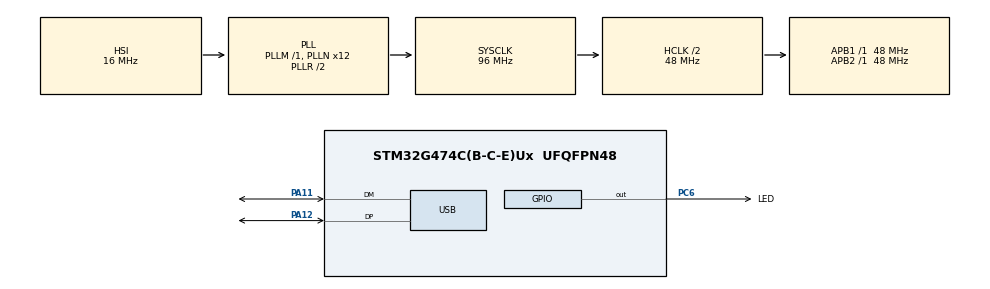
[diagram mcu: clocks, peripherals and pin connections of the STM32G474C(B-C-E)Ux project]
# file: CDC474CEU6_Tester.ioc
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Mcu.Family=STM32G4
Mcu.Name=STM32G474C(B-C-E)Ux
Mcu.Package=UFQFPN48
NVIC.PriorityGroup=NVIC_PRIORITYGROUP_4
NVIC.USB_LP_IRQn=true\:0\:0\:false\:false\:true\:false\:true\:true
PA11.Mode=Device
PA11.Signal=USB_DM
PA12.Mode=Device
PA12.Signal=USB_DP
PA13.Mode=Serial_Wire
PA13.Signal=SYS_JTMS-SWDIO
PA14.Mode=Serial_Wire
PA14.Signal=SYS_JTCK-SWCLK
PC6.GPIO_Label=LED
PC6.Signal=GPIO_Output
ProjectManager.HeapSize=0x200
ProjectManager.StackSize=0x400
ProjectManager.TargetToolchain=EWARM V8.50
RCC.ADC12Freq_Value=96000000
RCC.ADC345Freq_Value=96000000
RCC.AHBCLKDivider=RCC_SYSCLK_DIV2
RCC.AHBFreq_Value=48000000
RCC.APB1Freq_Value=48000000
RCC.APB1TimFreq_Value=48000000
RCC.APB2Freq_Value=48000000
RCC.APB2TimFreq_Value=48000000
RCC.CortexFreq_Value=48000000
RCC.EXTERNAL_CLOCK_VALUE=12288000
RCC.HCLKFreq_Value=48000000
RCC.HSE_VALUE=8000000
RCC.HSI48_VALUE=48000000
RCC.HSI_VALUE=16000000
RCC.LSE_VALUE=32768
RCC.PLLN=12
RCC.PLLQ=RCC_PLLQ_DIV4
RCC.SYSCLKFreq_VALUE=96000000
RCC.SYSCLKSource=RCC_SYSCLKSOURCE_PLLCLK
RCC.USBFreq_Value=48000000
RCC.VCOOutputFreq_Value=192000000
USB_DEVICE.CLASS_NAME_FS=CDC
USB_DEVICE.USBD_SELF_POWERED=0
USB_DEVICE.VirtualMode=Cdc
USB_DEVICE.VirtualModeFS=Cdc_FS
VP_SYS_VS_DBSignals.Mode=DisableDeadBatterySignals
VP_USB_DEVICE_VS_USB_DEVICE_CDC_FS.Mode=CDC_FS
board=custom

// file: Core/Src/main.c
/* USER CODE BEGIN Header */
/**
  ******************************************************************************
  * @file           : main.c
  * @brief          : Main program body
  ******************************************************************************
  * @attention
  *
  * Copyright (c) 2025 STMicroelectronics.
  * All rights reserved.
  *
  * This software is licensed under terms that can be found in the LICENSE file
  * in the root directory of this software component.
  * If no LICENSE file comes with this software, it is provided AS-IS.
  *
  ******************************************************************************
  */
/* USER CODE END Header */
#include "main.h"
#include "usb_device.h"

/* USER CODE BEGIN Includes */
#include "string.h"
#include "usbd_cdc_if.h"
/* USER CODE END Includes */

/* USER CODE BEGIN PV */
char * message = "Hello world!\n";
char buffer[256] = {0};
char ipbuff[256] = {0};
uint16_t msg_size = 0;
uint32_t counter = 0;
uint32_t ticks = 0;

extern USBD_HandleTypeDef hUsbDeviceFS;

/* USER CODE END PV */

void SystemClock_Config(void);
static void MX_GPIO_Init(void);

int main(void)
{

  /* MCU Configuration--------------------------------------------------------*/

  /* Reset of all peripherals, Initializes the Flash interface and the Systick. */
  HAL_Init();

  /* Configure the system clock */
  SystemClock_Config();

  /* Initialize all configured peripherals */
  MX_GPIO_Init();
  MX_USB_Device_Init();
  /* USER CODE BEGIN 2 */
  msg_size = strlen( message );
  ticks = uwTick;
  /* USER CODE END 2 */

  /* Infinite loop */
  /* USER CODE BEGIN WHILE */
  while (1)
  {
    if( (ipbuff[0]) == 'a' ) {
      ipbuff[0] = 0;
      counter = 0;
    }
    if( ipbuff[0] == 'b' ) {
      ipbuff[0] = 0;
      HAL_GPIO_TogglePin( LED_GPIO_Port, LED_Pin );
    }
    if( uwTick - ticks >= 1000 )
    {
      ticks = uwTick;

      sprintf( buffer, "Counter value is: %lu\n\r", counter++ );
      CDC_Transmit_FS( buffer, strlen( buffer) );
      HAL_Delay( 20 );
      sprintf( buffer, "...and counting.\n\r" );
      CDC_Transmit_FS( buffer, strlen( buffer) );
      HAL_Delay( 20 );
    }
    /* USER CODE END WHILE */

  }
}

void SystemClock_Config(void)
{
  RCC_OscInitTypeDef RCC_OscInitStruct = {0};
  RCC_ClkInitTypeDef RCC_ClkInitStruct = {0};

  /** Configure the main internal regulator output voltage
  */
  HAL_PWREx_ControlVoltageScaling(PWR_REGULATOR_VOLTAGE_SCALE1);

  /** Initializes the RCC Oscillators according to the specified parameters
  * in the RCC_OscInitTypeDef structure.
  */
  RCC_OscInitStruct.OscillatorType = RCC_OSCILLATORTYPE_HSI;
  RCC_OscInitStruct.HSIState = RCC_HSI_ON;
  RCC_OscInitStruct.HSICalibrationValue = RCC_HSICALIBRATION_DEFAULT;
  RCC_OscInitStruct.PLL.PLLState = RCC_PLL_ON;
  RCC_OscInitStruct.PLL.PLLSource = RCC_PLLSOURCE_HSI;
  RCC_OscInitStruct.PLL.PLLM = RCC_PLLM_DIV1;
  RCC_OscInitStruct.PLL.PLLN = 12;
  RCC_OscInitStruct.PLL.PLLP = RCC_PLLP_DIV2;
  RCC_OscInitStruct.PLL.PLLQ = RCC_PLLQ_DIV4;
  RCC_OscInitStruct.PLL.PLLR = RCC_PLLR_DIV2;
  if (HAL_RCC_OscConfig(&RCC_OscInitStruct) != HAL_OK)
  {
    Error_Handler();
  }

  /** Initializes the CPU, AHB and APB buses clocks
  */
  RCC_ClkInitStruct.ClockType = RCC_CLOCKTYPE_HCLK|RCC_CLOCKTYPE_SYSCLK
                              |RCC_CLOCKTYPE_PCLK1|RCC_CLOCKTYPE_PCLK2;
  RCC_ClkInitStruct.SYSCLKSource = RCC_SYSCLKSOURCE_PLLCLK;
  RCC_ClkInitStruct.AHBCLKDivider = RCC_SYSCLK_DIV2;
  RCC_ClkInitStruct.APB1CLKDivider = RCC_HCLK_DIV1;
  RCC_ClkInitStruct.APB2CLKDivider = RCC_HCLK_DIV1;

  if (HAL_RCC_ClockConfig(&RCC_ClkInitStruct, FLASH_LATENCY_1) != HAL_OK)
  {
    Error_Handler();
  }
}

static void MX_GPIO_Init(void)
{
  GPIO_InitTypeDef GPIO_InitStruct = {0};

  /* GPIO Ports Clock Enable */
  __HAL_RCC_GPIOC_CLK_ENABLE();
  __HAL_RCC_GPIOA_CLK_ENABLE();

  /*Configure GPIO pin Output Level */
  HAL_GPIO_WritePin(LED_GPIO_Port, LED_Pin, GPIO_PIN_RESET);

  /*Configure GPIO pin : LED_Pin */
  GPIO_InitStruct.Pin = LED_Pin;
  GPIO_InitStruct.Mode = GPIO_MODE_OUTPUT_PP;
  GPIO_InitStruct.Pull = GPIO_NOPULL;
  GPIO_InitStruct.Speed = GPIO_SPEED_FREQ_LOW;
  HAL_GPIO_Init(LED_GPIO_Port, &GPIO_InitStruct);

}

void Error_Handler(void)
{
  __disable_irq();
  while (1)
  {
  }
}
